# GD32E11x register map
File version: 1.0
CPU: CM4 r2p1, little endian, no MPU, FPU, 4 interrupt priority bits
Registers are 32-bit, read-write, reset 0x0 unless marked. A register's access mark holds for its fields unless they carry their own. Offsets are from the block's base; [hi:lo] are bit positions; {n}, {i} and the like mark numbered series.

## DBG — Debug support
Base 0xE0042000
0x00 ID ro — ID code register
  [31:0] ID_CODE — DBG ID code register
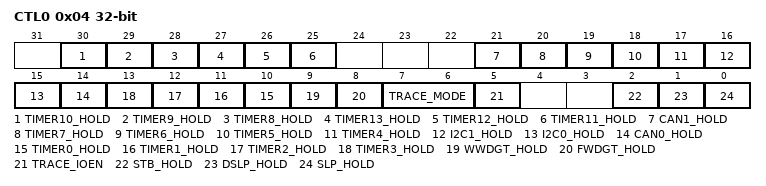
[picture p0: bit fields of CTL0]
0x04 CTL0 — Control register 0
  [30] TIMER10_HOLD — TIMER 10 hold bit
  [29] TIMER9_HOLD — TIMER 9 hold bit
  [28] TIMER8_HOLD — TIMER 8 hold bit
  [27] TIMER13_HOLD — TIMER 13 hold bit
  [26] TIMER12_HOLD — TIMER 12 hold bit
  [25] TIMER11_HOLD — TIMER 11 hold bit
  [21] CAN1_HOLD — CAN1 hold bit
  [20] TIMER7_HOLD — TIMER 7 hold bit
  [19] TIMER6_HOLD — TIMER 6 hold bit
  [18] TIMER5_HOLD — TIMER 5 hold bit
  [17] TIMER4_HOLD
  [16] I2C1_HOLD — I2C1 hold bit
  [15] I2C0_HOLD — I2C0 hold bit
  [14] CAN0_HOLD — CAN0 hold bit
  [n+10] TIMER{n}_HOLD (n=0..3) — TIMER {n} hold bit
  [9] WWDGT_HOLD — WWDGT hold bit
  [8] FWDGT_HOLD — FWDGT hold bit
  [7:6] TRACE_MODE — Trace pin allocation mode
  [5] TRACE_IOEN — Trace pin allocation enable
  [2] STB_HOLD — Standby mode hold register
  [1] DSLP_HOLD — Deep-sleep mode hold register
  [0] SLP_HOLD — Sleep mode hold register

## DMA0 — DMA controller
Base 0x40020000
Same registers: DMA1 0x40020400
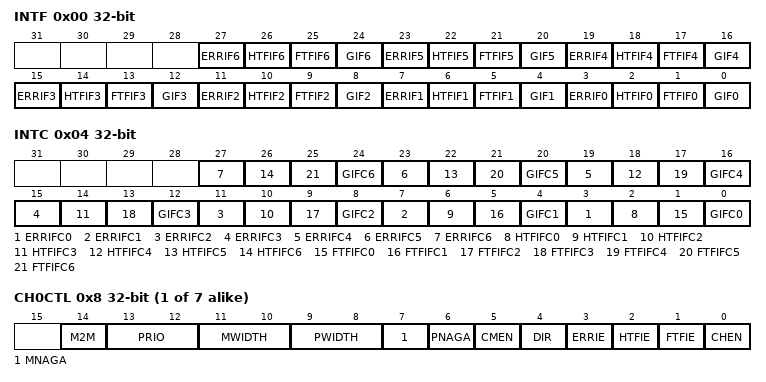
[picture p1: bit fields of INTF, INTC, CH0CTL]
0x00 INTF ro — Interrupt flag register
  [4n+3] ERRIF{n} (n=0..6) — Error flag of channel {n}
  [4n+2] HTFIF{n} (n=0..6) — Half transfer finish flag of channel {n}
  [4n+1] FTFIF{n} (n=0..6) — Full transfer finish flag of channe {n}
  [4n] GIF{n} (n=0..6) — Global interrupt flag of channel {n}
0x04 INTC wo — Interrupt flag clear register
  [4n+3] ERRIFC{n} (n=0..6) — Clear bit for error flag of channel {n}
  [4n+2] HTFIFC{n} (n=0..6) — Clear bit for half transfer finish flag of channel {n}
  [4n+1] FTFIFC{n} (n=0..6) — Clear bit for full transfer finish flag of channel {n}
  [4n] GIFC{n} (n=0..6) — Clear global interrupt flag of channel {n}
{0x8+0x14*i} CH{i}CTL (i=0..6) — Channel {i} control register
  [14] M2M — Memory to memory mode
  [13:12] PRIO — Priority level
  [11:10] MWIDTH — Transfer data size of memory
  [9:8] PWIDTH — Transfer data size of peripheral
  [7] MNAGA — Next address generation algorithm of memory
  [6] PNAGA — Next address generation algorithm of peripheral
  [5] CMEN — Circular mode enable
  [4] DIR — Transfer direction
  [3] ERRIE — Enable bit for channel error interrupt
  [2] HTFIE — Enable bit for channel half transfer finish interrupt
  [1] FTFIE — Enable bit for channel full transfer finish interrupt
  [0] CHEN — Channel enable
{0xC+0x14*i} CH{i}CNT (i=0..6) — Channel {i} counter register
  [15:0] CNT — Transfer counter
{0x10+0x14*i} CH{i}PADDR (i=0..6) — Channel {i} peripheral base address register
  [31:0] PADDR — Peripheral base address
{0x14+0x14*i} CH{i}MADDR (i=0..6) — Channel {i} memory base address register
  [31:0] MADDR — Memory base address

## EXMC — External memory controller
Base 0xA0000000
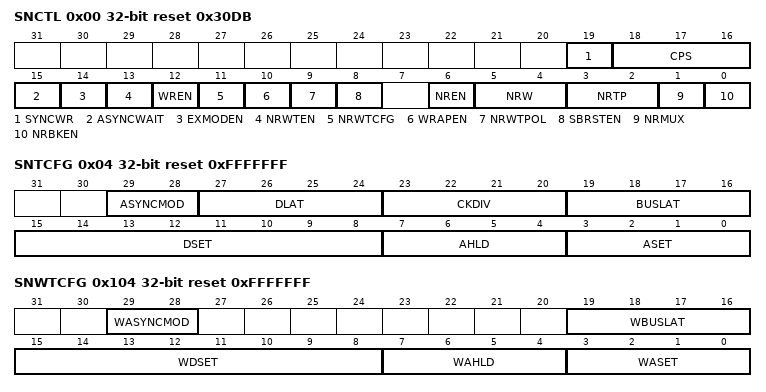
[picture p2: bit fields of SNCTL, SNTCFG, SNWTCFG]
0x00 SNCTL reset 0x30DB — SRAM/NOR Flash control registers
  [19] SYNCWR — synchronous write
  [18:16] CPS — CRAM page size
  [15] ASYNCWAIT — asynchronous wait
  [14] EXMODEN — extended mode enable
  [13] NRWTEN — NWAIT signal enable
  [12] WREN — write enable
  [11] NRWTCFG — NWAIT signal configuration
  [10] WRAPEN — wrapped burst mode enable
  [9] NRWTPOL — NWAIT signal polarity
  [8] SBRSTEN — synchronous burst enable
  [6] NREN — NOR Flash access enable
  [5:4] NRW — NOR region memory data bus width
  [3:2] NRTP — NOR region memory type
  [1] NRMUX — NOR region memory address/data multiplexing
  [0] NRBKEN — NOR region enable
0x04 SNTCFG reset 0xFFFFFFF — SRAM/NOR Flash timing configuration registers
  [29:28] ASYNCMOD — asynchronous access mode
  [27:24] DLAT — data latency for NOR Flash
  [23:20] CKDIV — synchronous clock divide ratio
  [19:16] BUSLAT — bus latency
  [15:8] DSET — data setup time
  [7:4] AHLD — address hold time
  [3:0] ASET — address setup time
0x104 SNWTCFG reset 0xFFFFFFF — SRAM/NOR write timing configuration registers
  [29:28] WASYNCMOD — asynchronous access mode
  [19:16] WBUSLAT — bus latency
  [15:8] WDSET — data setup time
  [7:4] WAHLD — address hold time
  [3:0] WASET — address setup time
